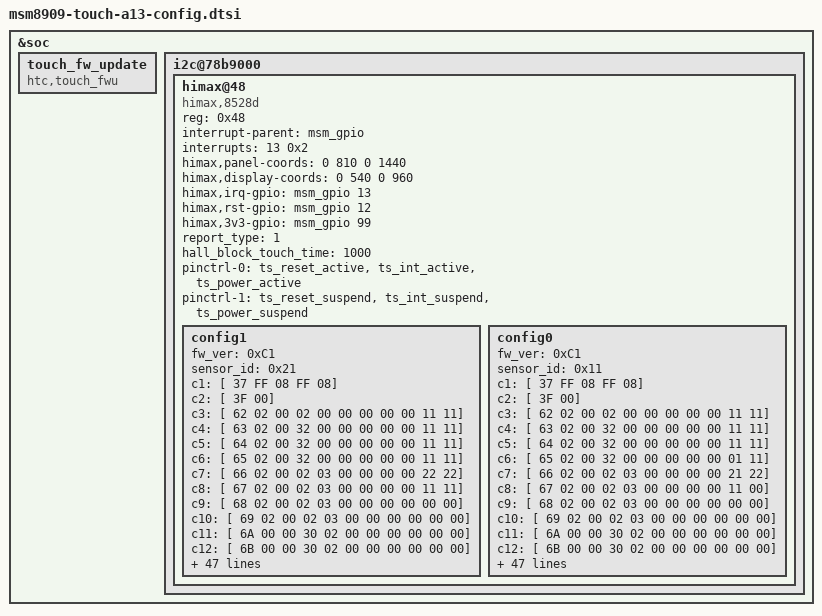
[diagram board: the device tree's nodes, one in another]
&soc {
	touch_fw_update {
		compatible = "htc,touch_fwu";
	};

	i2c@78b9000 { /* BLSP1 QUP5 */
		himax@48 {
			compatible		= "himax,8528d";
			reg			= <0x48>;
			interrupt-parent	= <&msm_gpio>;
			interrupts		= <13 0x2>;
			himax,panel-coords	= <0 810 0 1440>;
			himax,display-coords	= <0 540 0 960>;
			himax,irq-gpio		= <&msm_gpio 13 0x00>;
			himax,rst-gpio		= <&msm_gpio 12 0x00>;
			himax,3v3-gpio		= <&msm_gpio 99 0x00>;
			report_type		= <1>;
			hall_block_touch_time	= <1000>;	/* msec */
			pinctrl-names = "pmx_ts_active", "pmx_ts_suspend";
			pinctrl-0 = <&ts_reset_active &ts_int_active &ts_power_active>;
			pinctrl-1 = <&ts_reset_suspend &ts_int_suspend &ts_power_suspend>;

			config1 {	//Truly 2nd source
				fw_ver		= <0xC1>;
				sensor_id	= <0x21>;
				c1  = [ 37 FF 08 FF 08];
				c2  = [ 3F 00];
				c3  = [ 62 02 00 02 00 00 00 00 00 11 11];
				c4  = [ 63 02 00 32 00 00 00 00 00 11 11];
				c5  = [ 64 02 00 32 00 00 00 00 00 11 11];
				c6  = [ 65 02 00 32 00 00 00 00 00 11 11];
				c7  = [ 66 02 00 02 03 00 00 00 00 22 22];
				c8  = [ 67 02 00 02 03 00 00 00 00 11 11];
				c9  = [ 68 02 00 02 03 00 00 00 00 00 00];
				c10 = [ 69 02 00 02 03 00 00 00 00 00 00];
				c11 = [ 6A 00 00 30 02 00 00 00 00 00 00];
				c12 = [ 6B 00 00 30 02 00 00 00 00 00 00];
				c13 = [ 6C 00 00 30 02 00 00 00 00 00 00];
				c14 = [ 6D 00 00 00 02 00 00 00 00 00 00];
				c15 = [ 6E 00 00 00 02 00 00 00 00 00 00];
				c16 = [ 6F 01 00 21 00 00 00 00 00 00 00];
				c17 = [ 70 01 00 31 00 00 00 00 00 00 00];
				c18 = [ 7B 03];
				c19 = [ 7C 00 D8 0C];
				c20 = [ 7F 00 04 0A 0A 04 00 00 00];
				c21 = [ A4 94 62 94 86];
				c22 = [ B4 08 01 01 01 01 03 07 04 0F 04
					0F 04 0F 08];
				c23 = [ B9 01 36];
				c24 = [ BA 00];
				c25 = [ BB 00];
				c26 = [ BC 00 00 00 00];
				c27 = [ BD 04 0C];
				c28 = [ C2 10 00 00 00 00 00 00 00];
				c29 = [ C5 09 18 00 10 1B 1E 0B 1E 08 16];
				c30 = [ C6 1B 10 1A];
				c31 = [ C9 00 00 00 22 21 20 1D 1C 1B 1A
					19 18 2D 29 28 27 26 25 24 23
					00 00 00 00 00 00 00 00 00 00
					00 00 00 00 00 00 00 00 00 00
					00 00 00 00 00 00 00 00 00 00
					00 00 00 00 00 00 00 00 00 00
					00 00 00 00];
				c32 = [ CB 01 F5 FF FF 01 00 05 00 9F 00
					00 00];
				c33 = [ D0 06 01];
				c34 = [ D3 06 01];
				c35 = [ D5 29 00 00 00 00 00 00 00 00 00
					00 00 00 00 00 00];
				c36 = [ 40 21 5A
					5F 00 F2 10 00 00
					1C 0F 0F 0F 09 09 09 0F 0F 0F
					2F 2F 28 28 38 00 00 00 00 00
					00 00];
				c37 = [ 40 74 0A F0 84 85 00
					20 10 0F 0F 83 3C 00 00
					11 11 41 42
					18 48 00 18 00 00
					10 01 3C 64 00 00];
				c38 = [ 40 20 37 37 05 28 00 00 00
					04 06 24 08 08 00 00 00];
				c39 = [ 40 30 46 05 00 00 D8 0C 00 00 02
					03 00 00 00 00 00
					10 02 80 00 00 00 00 0C];
				c40 = [ 40 00 00 00 00 00 00 00 00
					BE 82 28 00
					0A 11 A0 13
					00 00 03 2A 05 A0];
				c41 = [ 40 0B AB 13 B1 66 E1 08 02 09 06
					1C 60 D6 0A
					0F 6A 1A 03 6D 66 00 02 DF 08
					9C 65 6B 00];
				c42 = [ 40 07 04 00 00 00 00 00 00];
				c43_1=[ 40 FF 02 FF FF FF 03 0E FF FF 04
					0C FF FF 05 0A FF FF 06 19 FF
					FF 07 17 FF FF 08 15 FF FF 09
					13];
				c43_2=[ 40 FF FF 1A 11 FF FF 18 0F FF
					FF 16 0D FF FF 14 FF FF FF 12
					FF FF 00 10 FF FF 01 FF 0B FF];
				c44_1=[ 40 33 00 C0 00 19 0A 28 00 00 00
					00 00 00 00 00 00 00 00 00 00
					11 C4 45 C5 48 5C 03 00 00 00
					5C];
				c44_2=[ 40 03 11 03 05 18];
				c45 = [ 40 00 00];
			};

			config0 {	//YFO 1st source
				fw_ver		= <0xC1>;
				sensor_id	= <0x11>;
				c1  = [ 37 FF 08 FF 08];
				c2  = [ 3F 00];
				c3  = [ 62 02 00 02 00 00 00 00 00 11 11];
				c4  = [ 63 02 00 32 00 00 00 00 00 11 11];
				c5  = [ 64 02 00 32 00 00 00 00 00 11 11];
				c6  = [ 65 02 00 32 00 00 00 00 00 01 11];
				c7  = [ 66 02 00 02 03 00 00 00 00 21 22];
				c8  = [ 67 02 00 02 03 00 00 00 00 11 00];
				c9  = [ 68 02 00 02 03 00 00 00 00 00 00];
				c10 = [ 69 02 00 02 03 00 00 00 00 00 00];
				c11 = [ 6A 00 00 30 02 00 00 00 00 00 00];
				c12 = [ 6B 00 00 30 02 00 00 00 00 00 00];
				c13 = [ 6C 00 00 30 02 00 00 00 00 00 00];
				c14 = [ 6D 00 00 00 02 00 00 00 00 00 00];
				c15 = [ 6E 00 00 00 02 00 00 00 00 00 00];
				c16 = [ 6F 01 00 21 00 00 00 00 00 00 00];
				c17 = [ 70 01 00 31 00 00 00 00 00 00 00];
				c18 = [ 7B 03];
				c19 = [ 7C 00 D8 0C];
				c20 = [ 7F 00 04 0A 0A 04 00 00 00];
				c21 = [ A4 94 62 94 86];
				c22 = [ B4 08 01 01 01 01 03 07 04 0F 04
					0F 04 0F 08];
				c23 = [ B9 01 36];
				c24 = [ BA 00];
				c25 = [ BB 00];
				c26 = [ BC 00 00 00 00];
				c27 = [ BD 04 0C];
				c28 = [ C2 10 00 00 00 00 00 00 00];
				c29 = [ C5 09 1E 00 10 1B 1E 0B 1E 08 16];
				c30 = [ C6 19 10 1A];
				c31 = [ C9 00 00 00 22 21 20 1D 1C 1B 1A
					19 18 2D 29 28 27 26 25 24 23
					00 00 00 00 00 00 00 00 00 00
					00 00 00 00 00 00 00 00 00 00
					00 00 00 00 00 00 00 00 00 00
					00 00 00 00 00 00 00 00 00 00
					00 00 00 00];
				c32 = [ CB 01 F5 FF FF 01 00 05 00 9F 00
					00 00];
				c33 = [ D0 06 01];
				c34 = [ D3 06 01];
				c35 = [ D5 29 00 00 00 00 00 00 00 00 00
					00 00 00 00 00 00];
				c36 = [ 40 04 5A
					5F 00 F2 10 00 00
					1C 0F 0F 0F 09 09 09 0F 0F 0F
					2F 2F 28 28 38 00 00 00 00 00
					00 00];
				c37 = [ 40 74 0A F0 84 85 00
					20 10 0F 0F 83 3C 00 00
					11 11 C1 42
					18 48 00 18 00 00
					10 01 3C 64 00 00];
				c38 = [ 40 10 37 37 05 40 00 00 00
					04 06 24 08 08 00 00 00];
				c39 = [ 40 30 46 05 00 00 D8 0C 00 00 02
					03 00 00 00 00 00
					10 02 80 00 00 00 00 0C];
				c40 = [ 40 00 00 00 00 00 00 00 00
					BE 82 28 00
					0A 11 A0 13
					00 00 03 2A 05 A0];
				c41 = [ 40 0B AB 13 B1 66 E1 08 02 09 06
					1C 60 D6 0A
					0F 6A 1A 03 6D 66 00 02 DF 08
					9C 65 6B 00];
				c42 = [ 40 05 04 04 00 00 00 00 00];
				c43_1=[ 40 FF 02 FF FF FF 03 0E FF FF 04
					0C FF FF 05 0A FF FF 06 19 FF
					FF 07 17 FF FF 08 15 FF FF 09
					13];
				c43_2=[ 40 FF FF 1A 11 FF FF 18 0F FF
					FF 16 0D FF FF 14 FF FF FF 12
					FF FF 00 10 FF FF 01 FF 0B FF];
				c44_1=[ 40 33 00 C0 00 19 0A 28 00 00 00
					00 00 00 00 00 00 00 00 00 00
					11 C4 45 F5 48 5C 03 00 00 00
					5C];
				c44_2=[ 40 03 11 03 05 18];
				c45 = [ 40 00 00];
			};
		};
	};
};
